# MIMXRT685S_cm33 register map
Vendor: nxp.com; File version: 1.0
CPU: CM33 r2p0, little endian, MPU, FPU, VTOR, 3 interrupt priority bits
Registers are 32-bit, read-write, reset 0x0 unless marked. A register's access mark holds for its fields unless they carry their own. Offsets are from the block's base; [hi:lo] are bit positions; {n}, {i} and the like mark numbered series; 'fields as' and 'values as' point back to an identical list.

## SYSCTL0 — system controller 0
Base 0x40002000
0x0C DSPSTALL reset 0x1
  [0] DSPSTALL — Run / Stall Register. . .
    0=RUN_MODE (Run (Normal) Mode.); 1=STALL_MODE
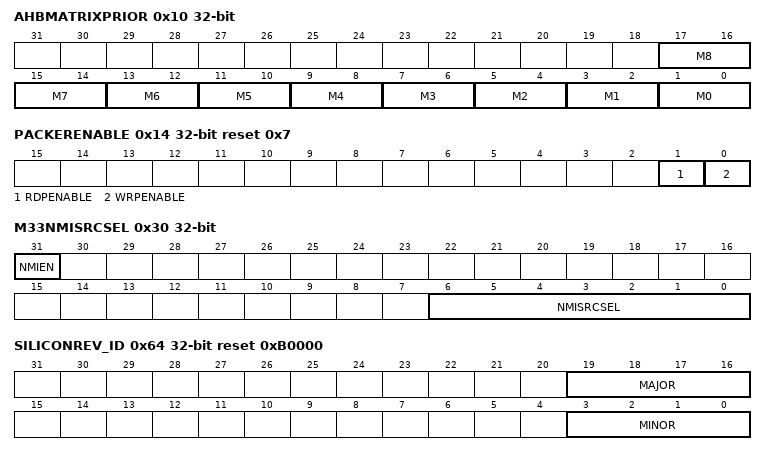
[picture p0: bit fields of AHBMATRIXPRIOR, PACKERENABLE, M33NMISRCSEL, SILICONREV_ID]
0x10 AHBMATRIXPRIOR — AHB matrix priority
  [2n+1:2n] M{n} (n=1..8) — Master {n} Priority. . . 0: 0, 1: 1, 2: 2, 3: 3.
  [1:0] M0 — Master 0 Priority. . . 0: 0, 1: 1, 2: 2, 3: 3. (0 High)
0x14 PACKERENABLE reset 0x7 — Packer enable for DSP RAM packer
  [1] RDPENABLE — Read Packer Enable
    0=DISABLED; 1=ENABLED
  [0] WRPENABLE — Write Packer Enable.
    0=DISABLED; 1=ENABLED
0x30 M33NMISRCSEL — M33 nmi source selection
  [31] NMIEN — NMI interrupt enable
    0=DISABLED (Disable NMI Interrupt); 1=ENABLED (Enable NMI Interrupt.)
  [6:0] NMISRCSEL — Selects one of the M33 interrupt sources as the NMI source. See M33 Interrupt Slot Table for Interrupt Slot Numers.
0x34 SYSTEM_STICK_CALIB — system stick calibration
  [25:0] SYSTEM_STICK_CALIB — Selects the system secure tick calibration value of the M33.
0x38 SYSTEM_NSTICK_CALIB — system nstick calibration
  [25:0] SYSTEM_NSTICK_CALIB — Selects the system non-secure tick calibration value of the M33.
0x60 PRODUCT_ID ro reset not defined
  [15:0] PRODUCT_ID — This register contains the product ID which is unique for each part number.
0x64 SILICONREV_ID ro reset 0xB0000
  [19:16] MAJOR — Silicon revision major tag. (IE, A, B, C, etc)
  [3:0] MINOR — Silicon revision minor tag. (IE, 0, 2, 3, etc)
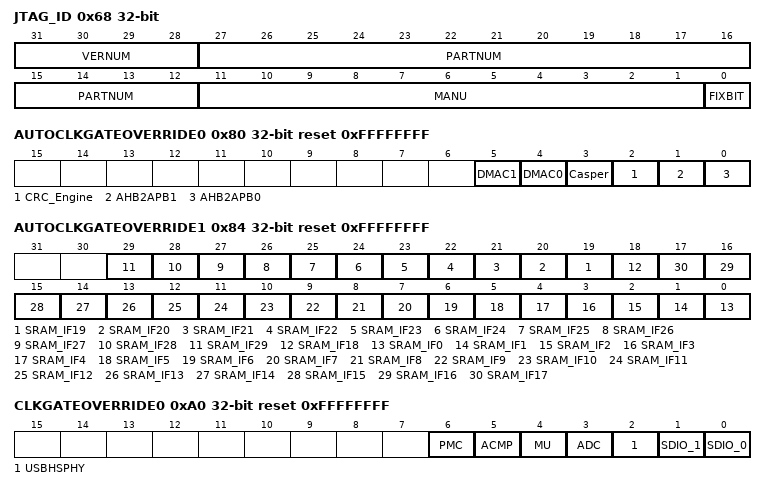
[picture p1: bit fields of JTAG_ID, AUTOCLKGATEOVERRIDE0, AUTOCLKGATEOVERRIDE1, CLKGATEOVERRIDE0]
0x68 JTAG_ID ro reset not defined
  [31:28] VERNUM — JTAG IDCODE version number
  [27:12] PARTNUM — JTAG IDCODE part number
  [11:1] MANU — JTAG IDCODE manufacturer identity
  [0] FIXBIT — JTAG IDCODE fix bit
0x80 AUTOCLKGATEOVERRIDE0 reset 0xFFFFFFFF — auto clock gating override 0
  [all] fields
    0=ENABLED (Enable Auto-Clk); 1=DISABLED (Disable Auto-Clk)
  [5] DMAC1 — auto clock gating enable
  [4] DMAC0 — auto clock gating enable
  [3] Casper — auto clock gating enable
  [2] CRC_Engine — auto clock gating enable
  [1] AHB2APB1 — auto clock gating enable
  [0] AHB2APB0 — auto clock gating enable
0x84 AUTOCLKGATEOVERRIDE1 reset 0xFFFFFFFF — auto clock gating override 1
  [n] SRAM_IF{n} (n=19..29) — auto clock gating enable
    0=ENABLED (Enable Auto-Clk); 1=DISABLED (Disable Auto-Clk)
  [18] SRAM_IF18 — auto clock gating enable
  [n] SRAM_IF{n} (n=0..17) — auto clock gating enable
    0=ENABLED (Enable Auto-Clk); 1=DISABLED (Disable Auto-Clk)
0xA0 CLKGATEOVERRIDE0 reset 0xFFFFFFFF — Clock gate override 0
  [all] fields
    0=NO_EFFECT; 1=OVERRIDE
  [6] PMC — pmc clock override
  [5] ACMP — acomparator clock override
  [4] MU — mu clock override
  [3] ADC — adc clock override
  [2] USBHSPHY — usbhsphy clock override
  [1] SDIO_1 — sdio 1 clock override
  [0] SDIO_0 — sdio 0 clock override
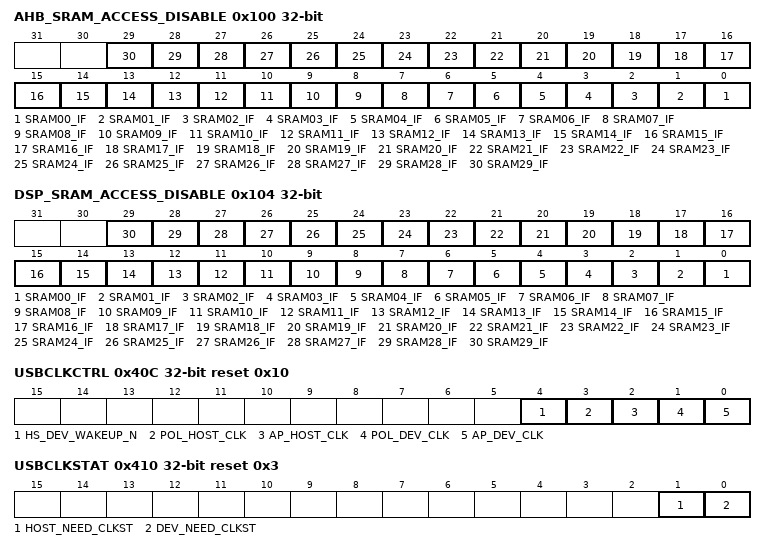
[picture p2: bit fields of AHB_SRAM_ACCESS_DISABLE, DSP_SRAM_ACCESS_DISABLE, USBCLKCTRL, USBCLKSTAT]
0x100 AHB_SRAM_ACCESS_DISABLE
  [all] fields
    0=ENABLED; 1=DISABLED
  [n] SRAM{n:02}_IF (n=0..29)
0x104 DSP_SRAM_ACCESS_DISABLE
  [all] fields
    0=ENABLED; 1=DISABLED
  [n] SRAM{n:02}_IF (n=0..29)
0x138 AHB_FLEXSPI_ACCESS_DISABLE — AHB Flexspi access control
  [0] AHB_FLEXSPI_ACCESS_DISABLE
    0=ENABLE (Enable AHB access to FLEXSPI); 1=DISABLE (Disable AHB access to FLEXSPI)
0x13C DSP_FLEXSPI_ACCESS_DISABLE — DSP Flexspi access control
  [0] DSP_FLEXSPI_ACCESS_DISABLE
    0=ENABLE (Enable DSP access to FLEXSPI); 1=DISABLE (Disable DSP access to FLEXSPI)
0x380 FLEXSPI_BOOTROM_SCRATCH0 — FLEXSPI NOR flash configure context register
  [31:0] scratch
0x40C USBCLKCTRL reset 0x10 — USB clock control
  [4] HS_DEV_WAKEUP_N — External user wake-up signal for device mode; asserting this signal (active low) will result in exiting the low power mode; input to asynchronous control logic
    0=FORCE_TO_WAKEUP (Forces USB0 PHY to wake-up.); 1=NORMAL (Normal USB0 PHY behavior.)
  [3] POL_HOST_CLK — USB0 HOST need clock polarity for triggering the USB1 wake-up interrupt
    0=FALLING_EDGE (Falling edge of host need_clock triggers wake-up.); 1=RISING_EDGE (Rising edge of host need_clock triggers wake-up.)
  [2] AP_HOST_CLK — USB0 Host need clock signal control
    0=UNDER_HW_CTRL (Under hardware control.); 1=FORCED_HIGH
  [1] POL_DEV_CLK — USB0 Device need clock polarity for triggering the USB1 wake-up interrupt
    0=FALLING_EDGE (Falling edge of device need_clock triggers wake-up.); 1=RISING_EDGE (Rising edge of device need_clock triggers wake-up.)
  [0] AP_DEV_CLK — USB0 Device need clock signal control
    0=UNDER_HW_CTRL (Under hardware control.); 1=FORCED_HIGH
0x410 USBCLKSTAT reset 0x3 — USB clock status
  [1] HOST_NEED_CLKST ro — USB Device Host USB_NEEDCLK signal status:
    0=LOW; 1=HIGH
  [0] DEV_NEED_CLKST ro — USB Device USB_NEEDCLK signal status:
    0=LOW; 1=HIGH
0x414 USBPHYPLL0LOCKTIMEDIV2 reset 0xCAFE — USB PHY PLL0 lock time division 2
  [15:0] LOCKTIMEDIV2 — USBPHYPLL0 Lock Time: Programmed lock time is in uS (micro-seconds) and is programmed as half the actual lock time value
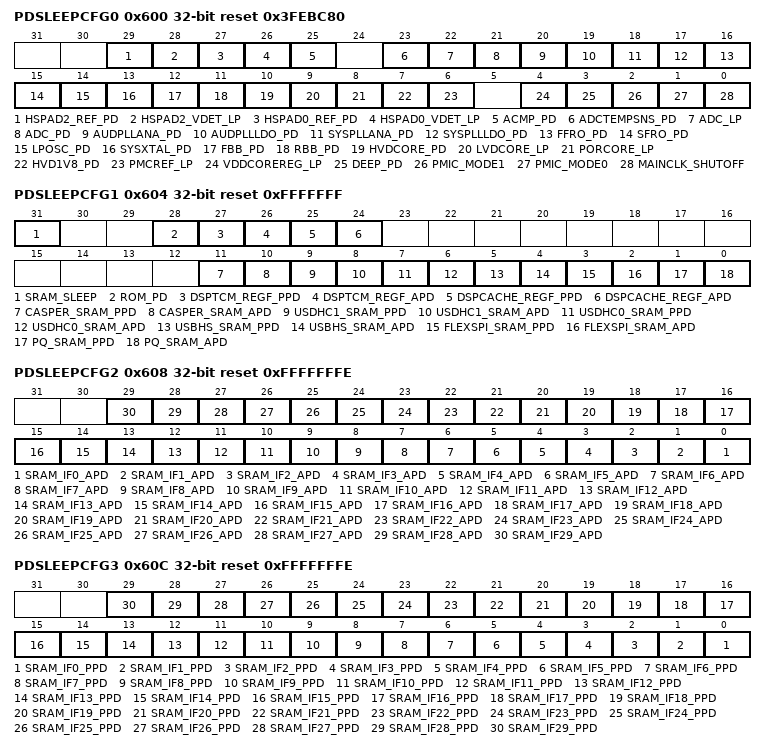
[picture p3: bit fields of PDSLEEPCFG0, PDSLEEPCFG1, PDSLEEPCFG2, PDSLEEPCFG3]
0x600 PDSLEEPCFG0 reset 0x3FEBC80 — Sleep configuration 0
  [29] HSPAD2_REF_PD
    0=ENABLED (High Speed Pad VREF Enabled); 1=POWER_DOWN (High Speed Pad VREF in Power Down)
  [28] HSPAD2_VDET_LP
    0=NORMAL_MODE (High Speed Pad VDET in Normal Mode); 1=SLEEP_MODE (High Speed Pad VDET in Sleep Mode)
  [27] HSPAD0_REF_PD
    values as HSPAD2_REF_PD
  [26] HSPAD0_VDET_LP
    values as HSPAD2_VDET_LP
  [25] ACMP_PD
    0=ENABLED; 1=POWER_DOWN
  [23] ADCTEMPSNS_PD
    0=ENABLED; 1=POWER_DOWN
  [22] ADC_LP
    0=ENABLED; 1=POWER_DOWN
  [21] ADC_PD
    0=ENABLED; 1=POWER_DOWN
  [20] AUDPLLANA_PD
    0=ENABLED; 1=POWER_DOWN
  [19] AUDPLLLDO_PD
    0=ENABLED; 1=POWER_DOWN
  [18] SYSPLLANA_PD
    0=ENABLED; 1=POWER_DOWN
  [17] SYSPLLLDO_PD
    0=ENABLED; 1=POWER_DOWN
  [16] FFRO_PD
    0=ENABLED; 1=POWER_DOWN
  [15] SFRO_PD
    0=ENABLED; 1=POWER_DOWN
  [14] LPOSC_PD
    0=ENABLED; 1=POWER_DOWN
  [13] SYSXTAL_PD
    0=ENABLED; 1=POWER_DOWN
  [12] FBB_PD — Writes to this bit in PDRUNCFG, but not PDSLEEPCFG, can be disabled by an OTP bit.
    0=ENABLED; 1=POWER_DOWN
  [11] RBB_PD — Writes to this bit in PDRUNCFG, but not PDSLEEPCFG, can be disabled by an OTP bit.
    0=ENABLED; 1=POWER_DOWN
  [10] HVDCORE_PD
    0=ENABLED; 1=POWER_DOWN
  [9] LVDCORE_LP
    0=HP_MODE (LVD0V85 HP Mode); 1=LP_MODE (LVD0V85 LP Mode.)
  [8] PORCORE_LP
    0=HP_MODE (LVD0V6 HP Mode); 1=LP_MODE (LVD0V6 LP Mode)
  [7] HVD1V8_PD
    0=ENABLED; 1=POWER_DOWN
  [6] PMCREF_LP
    0=HP_MODE (PMCREF HP Mode); 1=LP_MODE (PMCREF LP Mode)
  [4] VDDCOREREG_LP
    0=HP_MODE (VDDCOREREG HP Mode); 1=LP_MODE
  [3] DEEP_PD
    0=ENABLED; 1=POWER_DOWN
  [2] PMIC_MODE1
    0=SET_MODE1_0 (Set Mode1 to 0.); 1=SET_MODE1_1 (Set Mode1 to 1.)
  [1] PMIC_MODE0
    0=SET_MODE0_0 (Set Mode0 to '0'.); 1=SET_MODE0_1 (Set Mode0 to '1'.)
  [0] MAINCLK_SHUTOFF — main clock shut off
    0=CLOCK_ENABLED (Clocks enabled); 1=CLOCK_GATED (Clocks gated)
0x604 PDSLEEPCFG1 reset 0xFFFFFFF — Sleep configuration 1
  [31] SRAM_SLEEP — Needed when vddcore can be smaller than 0
    0=NORMAL_MODE (RAM Normal Mode); 1=SLEEP_MODE (RAM Sleep Mode.)
  [28] ROM_PD — array power and periph power
    0=ENABLED; 1=POWER_DOWN
  [27] DSPTCM_REGF_PPD — Peiph power
    0=ENABLED; 1=POWER_DOWN
  [26] DSPTCM_REGF_APD — Array power
    0=ENABLED; 1=POWER_DOWN
  [25] DSPCACHE_REGF_PPD — Peiph power
    0=ENABLED; 1=POWER_DOWN
  [24] DSPCACHE_REGF_APD — Array power
    0=ENABLED; 1=POWER_DOWN
  [11] CASPER_SRAM_PPD — Peiph power
    0=ENABLED; 1=POWER_DOWN
  [10] CASPER_SRAM_APD — Array power
    0=ENABLED; 1=POWER_DOWN
  [9] USDHC1_SRAM_PPD — Peiph power
    0=ENABLED; 1=POWER_DOWN
  [8] USDHC1_SRAM_APD — Array power
    0=ENABLED; 1=POWER_DOWN
  [7] USDHC0_SRAM_PPD — Peiph power
    0=ENABLED; 1=POWER_DOWN
  [6] USDHC0_SRAM_APD — Array power
    0=ENABLED; 1=POWER_DOWN
  [5] USBHS_SRAM_PPD — Peiph power
    0=ENABLED; 1=POWER_DOWN
  [4] USBHS_SRAM_APD — Array power
    0=ENABLED; 1=POWER_DOWN
  [3] FLEXSPI_SRAM_PPD — Peiph power
    0=ENABLED; 1=POWER_DOWN
  [2] FLEXSPI_SRAM_APD — Array power
    0=ENABLED; 1=POWER_DOWN
  [1] PQ_SRAM_PPD — Peiph power
    0=ENABLED; 1=POWER_DOWN
  [0] PQ_SRAM_APD — Array power
    0=ENABLED; 1=POWER_DOWN
0x608 PDSLEEPCFG2 reset 0xFFFFFFFE — Sleep configuration 2
  [all] fields
    0=ENABLED; 1=POWER_DOWN
  [n] SRAM_IF{n}_APD (n=0..29) — Array Power
0x60C PDSLEEPCFG3 reset 0xFFFFFFFE — Sleep configuration 3
  [all] fields
    0=ENABLED; 1=POWER_DOWN
  [n] SRAM_IF{n}_PPD (n=0..29) — Periph Power
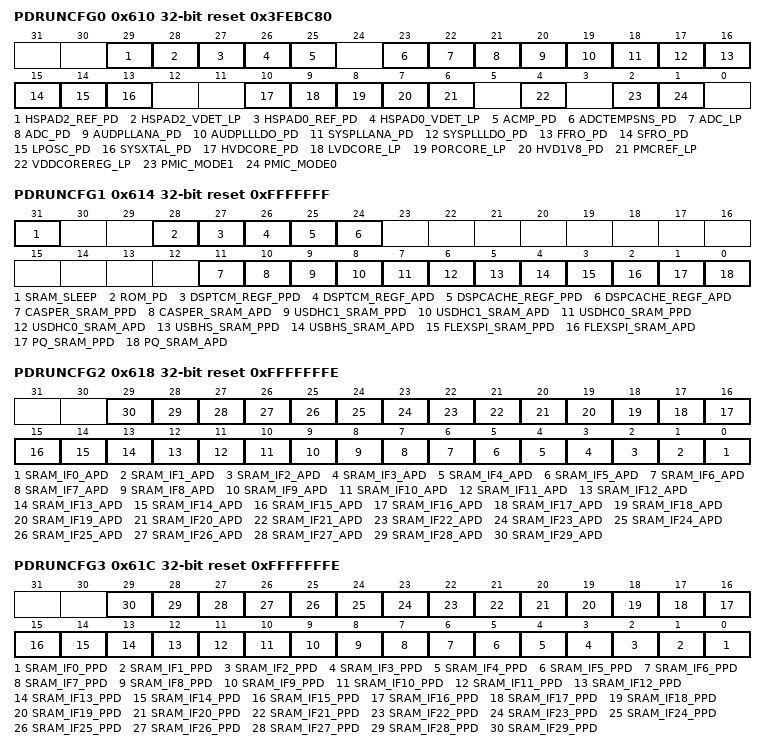
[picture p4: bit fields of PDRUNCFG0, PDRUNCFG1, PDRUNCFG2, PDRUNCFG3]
0x610 PDRUNCFG0 reset 0x3FEBC80 — Run configuration 0
  [29] HSPAD2_REF_PD — High speed Pad vdde2 reference blocks
    values as PDSLEEPCFG0.HSPAD2_REF_PD
  [28] HSPAD2_VDET_LP — High Speed Pad vdde2 voltage detect block
    values as PDSLEEPCFG0.HSPAD2_VDET_LP
  [27] HSPAD0_REF_PD — High speed Pad vdde0 reference blocks
    values as PDSLEEPCFG0.HSPAD2_REF_PD
  [26] HSPAD0_VDET_LP — High Speed Pad vdde0 voltage detect block
    values as PDSLEEPCFG0.HSPAD2_VDET_LP
  [25] ACMP_PD
    0=ENABLED; 1=POWER_DOWN
  [23] ADCTEMPSNS_PD
    0=ENABLED; 1=POWER_DOWN
  [22] ADC_LP
    0=ENABLED; 1=POWER_DOWN
  [21] ADC_PD
    0=ENABLED; 1=POWER_DOWN
  [20] AUDPLLANA_PD
    0=ENABLED; 1=POWER_DOWN
  [19] AUDPLLLDO_PD
    0=ENABLED; 1=POWER_DOWN
  [18] SYSPLLANA_PD
    0=ENABLED; 1=POWER_DOWN
  [17] SYSPLLLDO_PD
    0=ENABLED; 1=POWER_DOWN
  [16] FFRO_PD
    0=ENABLED; 1=POWER_DOWN
  [15] SFRO_PD
    0=ENABLED; 1=POWER_DOWN
  [14] LPOSC_PD
    0=ENABLED; 1=POWER_DOWN
  [13] SYSXTAL_PD
    0=ENABLED; 1=POWER_DOWN
  [10] HVDCORE_PD
    0=ENABLED; 1=POWER_DOWN
  [9] LVDCORE_LP
    0=HP_MODE (LVD0V85 HP Mode); 1=LP_MODE (LVD0V85 LP Mode.)
  [8] PORCORE_LP
    0=HP_MODE (LVD0V6 HP Mode); 1=LP_MODE (LVD0V6 LP Mode)
  [7] HVD1V8_PD
    0=ENABLED; 1=POWER_DOWN
  [6] PMCREF_LP
    0=HP_MODE (PMCREF HP Mode); 1=LP_MODE (PMCREF LP Mode)
  [4] VDDCOREREG_LP
    0=HP_MODE (VDDCOREREG HP Mode); 1=LP_MODE
  [2] PMIC_MODE1
    values as PDSLEEPCFG0.PMIC_MODE1
  [1] PMIC_MODE0
    0=SET_MODE0_0 (Set Mode0 to 0.); 1=SET_MODE0_1 (Set Mode0 to 1.)
0x614 PDRUNCFG1 reset 0xFFFFFFF — Run configuration 1
  fields as PDSLEEPCFG1
0x618 PDRUNCFG2 reset 0xFFFFFFFE — Run configuration 2
  fields as PDSLEEPCFG2
0x61C PDRUNCFG3 reset 0xFFFFFFFE — Run configuration 3
  fields as PDSLEEPCFG3
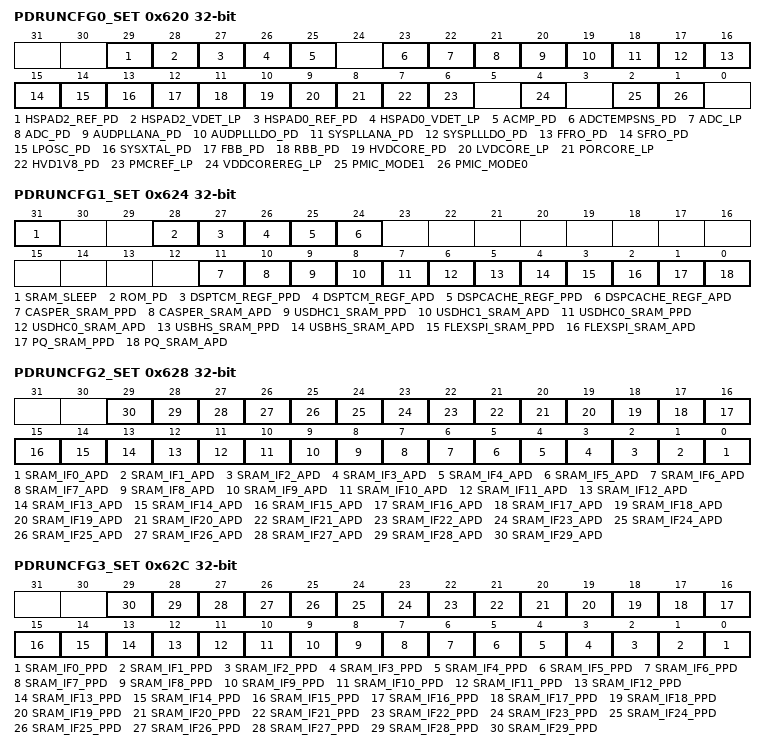
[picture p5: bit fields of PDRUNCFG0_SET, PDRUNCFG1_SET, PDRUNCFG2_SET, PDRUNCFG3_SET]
0x620 PDRUNCFG0_SET wo reset not defined — Run configuration 0 set
  [all] fields
    0=NO_EFFECT; 1=SET_PDRUNCFG0 (Sets the PDRUNCFG0 Bit)
  [29] HSPAD2_REF_PD
  [28] HSPAD2_VDET_LP
  [27] HSPAD0_REF_PD
  [26] HSPAD0_VDET_LP
  [25] ACMP_PD
  [23] ADCTEMPSNS_PD
  [22] ADC_LP
  [21] ADC_PD
  [20] AUDPLLANA_PD
  [19] AUDPLLLDO_PD
  [18] SYSPLLANA_PD
  [17] SYSPLLLDO_PD
  [16] FFRO_PD
  [15] SFRO_PD
  [14] LPOSC_PD
  [13] SYSXTAL_PD
  [12] FBB_PD
  [11] RBB_PD
  [10] HVDCORE_PD
  [9] LVDCORE_LP
  [8] PORCORE_LP
  [7] HVD1V8_PD
  [6] PMCREF_LP
  [4] VDDCOREREG_LP
  [2] PMIC_MODE1
  [1] PMIC_MODE0
0x624 PDRUNCFG1_SET wo reset not defined — Run configuration 1 set
  [all] fields
    0=NO_EFFECT; 1=SET_PDRUNCFG1 (Sets the PDRUNCFG1 Bit)
  [31] SRAM_SLEEP
  [28] ROM_PD — array power and periph power
  [27] DSPTCM_REGF_PPD — Peiph power
  [26] DSPTCM_REGF_APD — Array power
  [25] DSPCACHE_REGF_PPD — Peiph power
  [24] DSPCACHE_REGF_APD — Array power
  [11] CASPER_SRAM_PPD — Peiph power
  [10] CASPER_SRAM_APD — Array power
  [9] USDHC1_SRAM_PPD — Peiph power
  [8] USDHC1_SRAM_APD — Array power
  [7] USDHC0_SRAM_PPD — Peiph power
  [6] USDHC0_SRAM_APD — Array power
  [5] USBHS_SRAM_PPD — Peiph power
  [4] USBHS_SRAM_APD — Array power
  [3] FLEXSPI_SRAM_PPD — Peiph power
  [2] FLEXSPI_SRAM_APD — Array power
  [1] PQ_SRAM_PPD — Peiph power
  [0] PQ_SRAM_APD — Array power
0x628 PDRUNCFG2_SET wo reset not defined — Run configuration 2 set
  [all] fields
    0=NO_EFFECT; 1=SET_PDRUNCFG2 (Sets the PDRUNCFG2 Bit)
  [n] SRAM_IF{n}_APD (n=0..29) — Array Power
0x62C PDRUNCFG3_SET wo reset not defined — Run configuration 3 set
  [all] fields
    0=NO_EFFECT; 1=SET_PDRUNCFG3 (Sets the PDRUNCFG3 Bit)
  [n] SRAM_IF{n}_PPD (n=0..29) — Periph Power
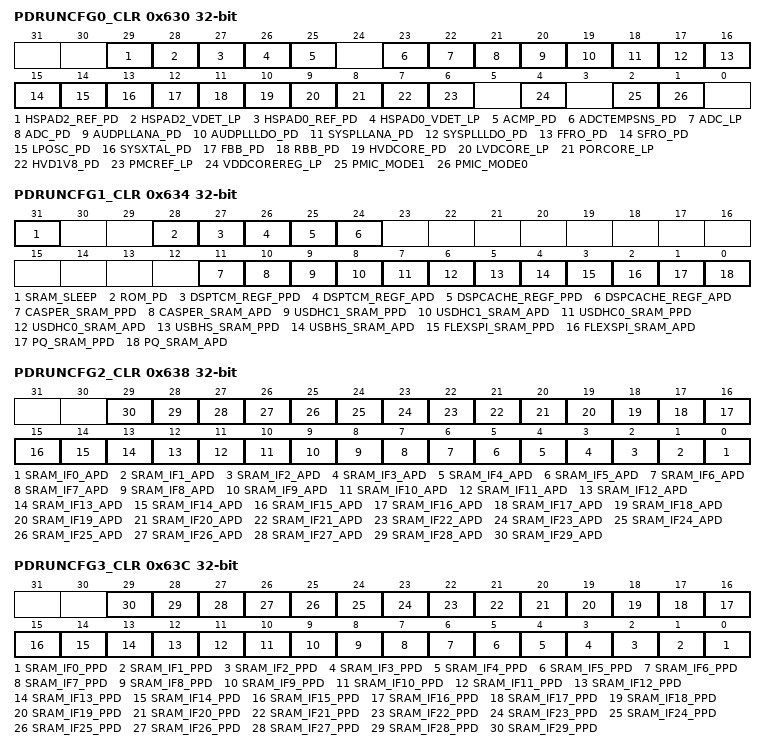
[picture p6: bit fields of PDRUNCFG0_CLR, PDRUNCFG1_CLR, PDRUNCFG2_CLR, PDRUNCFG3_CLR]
0x630 PDRUNCFG0_CLR wo reset not defined — Run configuration 0 clear
  [all] fields
    0=NO_EFFECT; 1=CLR_PDRUNCFG0 (Clears the PDRUNCFG0 Bit)
  [29] HSPAD2_REF_PD
  [28] HSPAD2_VDET_LP
  [27] HSPAD0_REF_PD
  [26] HSPAD0_VDET_LP
  [25] ACMP_PD
  [23] ADCTEMPSNS_PD
  [22] ADC_LP
  [21] ADC_PD
  [20] AUDPLLANA_PD
  [19] AUDPLLLDO_PD
  [18] SYSPLLANA_PD
  [17] SYSPLLLDO_PD
  [16] FFRO_PD
  [15] SFRO_PD
  [14] LPOSC_PD
  [13] SYSXTAL_PD
  [12] FBB_PD
  [11] RBB_PD
  [10] HVDCORE_PD
  [9] LVDCORE_LP
  [8] PORCORE_LP
  [7] HVD1V8_PD
  [6] PMCREF_LP
  [4] VDDCOREREG_LP
  [2] PMIC_MODE1
  [1] PMIC_MODE0
0x634 PDRUNCFG1_CLR wo reset not defined — Run configuration 1 clear
  [all] fields
    0=NO_EFFECT; 1=CLR_PDRUNCFG1 (Clears the PDRUNCFG1 Bit)
  [31] SRAM_SLEEP
  [28] ROM_PD — array power and periph power
  [27] DSPTCM_REGF_PPD — Peiph power
  [26] DSPTCM_REGF_APD — Array power
  [25] DSPCACHE_REGF_PPD — Peiph power
  [24] DSPCACHE_REGF_APD — Array power
  [11] CASPER_SRAM_PPD — Peiph power
  [10] CASPER_SRAM_APD — Array power
  [9] USDHC1_SRAM_PPD — Peiph power
  [8] USDHC1_SRAM_APD — Peiph power
  [7] USDHC0_SRAM_PPD — Array power
  [6] USDHC0_SRAM_APD — Array power
  [5] USBHS_SRAM_PPD — Peiph power
  [4] USBHS_SRAM_APD — Array power
  [3] FLEXSPI_SRAM_PPD — Peiph power
  [2] FLEXSPI_SRAM_APD — Array power
  [1] PQ_SRAM_PPD — Peiph power
  [0] PQ_SRAM_APD — Array power
0x638 PDRUNCFG2_CLR wo reset not defined — Run configuration 2 clear
  [all] fields
    0=NO_EFFECT; 1=CLR_PDRUNCFG2 (Clears the PDRUNCFG2 Bit)
  [n] SRAM_IF{n}_APD (n=0..29) — Array Power
0x63C PDRUNCFG3_CLR wo reset not defined — Run configuration 3 clear
  [all] fields
    0=NO_EFFECT; 1=CLR_PDRUNCFG3 (Clears the PDRUNCFG3 Bit)
  [n] SRAM_IF{n}_PPD (n=0..29) — Periph Power
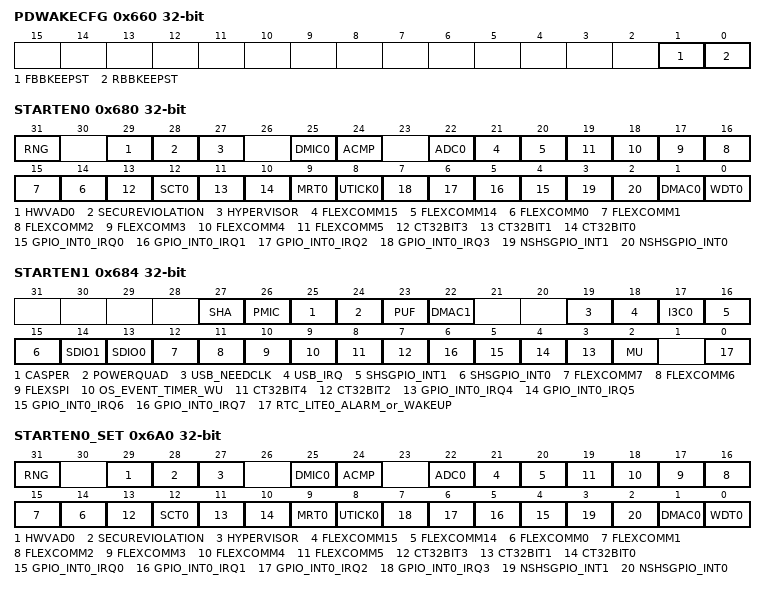
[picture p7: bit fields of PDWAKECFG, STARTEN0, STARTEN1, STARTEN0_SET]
0x660 PDWAKECFG — PD Wake Configuration
  [1] FBBKEEPST — FBB mode on wakeup
    0=Use value of FBB_PD in PDRUNCFG on wakeup; 1=Copy PDSLEEPCFG FBB_PD value to PDRUNCFG FBB_PD on wakeup to keep FBB state
  [0] RBBKEEPST — RBB mode on wakeup
    0=Use value of RBB_PD in PDRUNCFG on wakeup; 1=Copy PDSLEEPCFG RBB_PD value to PDRUNCFG RBB_PD on wakeup to keep RBB state
0x680 STARTEN0 — Start enable 0
  [all] fields
    0=DISABLED (disbale); 1=ENABLED
  [31] RNG
  [29] HWVAD0
  [28] SECUREVIOLATION
  [27] HYPERVISOR
  [25] DMIC0
  [24] ACMP
  [22] ADC0
  [21] FLEXCOMM15
  [20] FLEXCOMM14
  [n+14] FLEXCOMM{n} (n=0..5)
  [13] CT32BIT3
  [12] SCT0
  [11] CT32BIT1
  [10] CT32BIT0
  [9] MRT0
  [8] UTICK0
  [n+4] GPIO_INT0_IRQ{n} (n=0..3)
  [3] NSHSGPIO_INT1
  [2] NSHSGPIO_INT0
  [1] DMAC0
  [0] WDT0
0x684 STARTEN1 — Start enable 1
  [all] fields
    0=DISABLED (disbale); 1=ENABLED
  [27] SHA
  [26] PMIC
  [25] CASPER
  [24] POWERQUAD
  [23] PUF
  [22] DMAC1
  [19] USB_NEEDCLK
  [18] USB_IRQ
  [17] I3C0
  [16] SHSGPIO_INT1
  [15] SHSGPIO_INT0
  [14] SDIO1
  [13] SDIO0
  [12] FLEXCOMM7
  [11] FLEXCOMM6
  [10] FLEXSPI
  [9] OS_EVENT_TIMER_WU
  [8] CT32BIT4
  [7] CT32BIT2
  [n-1] GPIO_INT0_IRQ{n} (n=4..7)
  [2] MU
  [0] RTC_LITE0_ALARM_or_WAKEUP
0x6A0 STARTEN0_SET wo reset not defined — Start enable 0 set
  [all] fields
    0=NO_EFFECT; 1=SET_START_EN0 (Sets the START_EN0 Bit)
  [31] RNG
  [29] HWVAD0
  [28] SECUREVIOLATION
  [27] HYPERVISOR
  [25] DMIC0
  [24] ACMP
  [22] ADC0
  [21] FLEXCOMM15
  [20] FLEXCOMM14
  [n+14] FLEXCOMM{n} (n=0..5)
  [13] CT32BIT3
  [12] SCT0
  [11] CT32BIT1
  [10] CT32BIT0
  [9] MRT0
  [8] UTICK0
  [n+4] GPIO_INT0_IRQ{n} (n=0..3)
  [3] NSHSGPIO_INT1
  [2] NSHSGPIO_INT0
  [1] DMAC0
  [0] WDT0
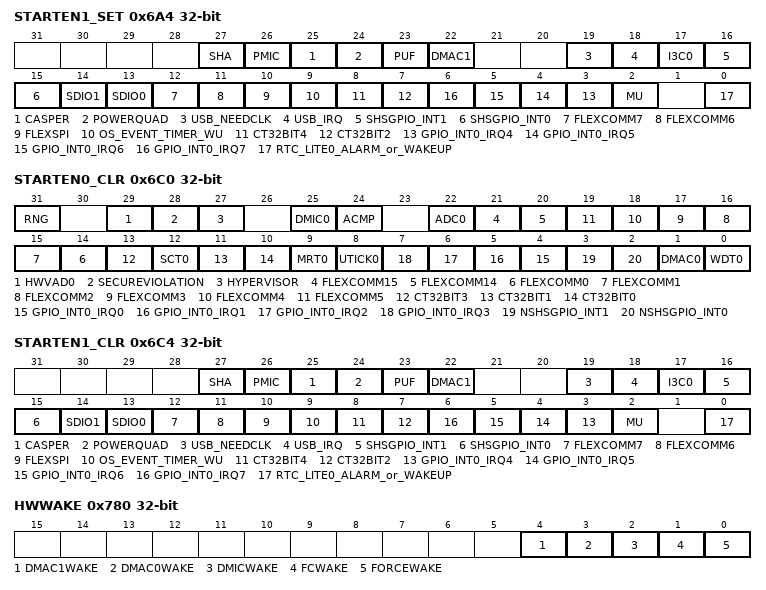
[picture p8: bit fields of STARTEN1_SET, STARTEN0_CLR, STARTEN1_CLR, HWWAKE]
0x6A4 STARTEN1_SET wo reset not defined — Start enable 1 set
  [all] fields
    0=NO_EFFECT; 1=SET_START_EN1 (Sets the START_EN1 Bit)
  [27] SHA
  [26] PMIC
  [25] CASPER
  [24] POWERQUAD
  [23] PUF
  [22] DMAC1
  [19] USB_NEEDCLK
  [18] USB_IRQ
  [17] I3C0
  [16] SHSGPIO_INT1
  [15] SHSGPIO_INT0
  [14] SDIO1
  [13] SDIO0
  [12] FLEXCOMM7
  [11] FLEXCOMM6
  [10] FLEXSPI
  [9] OS_EVENT_TIMER_WU
  [8] CT32BIT4
  [7] CT32BIT2
  [n-1] GPIO_INT0_IRQ{n} (n=4..7)
  [2] MU
  [0] RTC_LITE0_ALARM_or_WAKEUP
0x6C0 STARTEN0_CLR wo reset not defined — Start enable 0 clear
  [all] fields
    0=NO_EFFECT; 1=CLR_START_EN0 (Clears the START_EN0 Bit)
  [31] RNG
  [29] HWVAD0
  [28] SECUREVIOLATION
  [27] HYPERVISOR
  [25] DMIC0
  [24] ACMP
  [22] ADC0
  [21] FLEXCOMM15
  [20] FLEXCOMM14
  [n+14] FLEXCOMM{n} (n=0..5)
  [13] CT32BIT3
  [12] SCT0
  [11] CT32BIT1
  [10] CT32BIT0
  [9] MRT0
  [8] UTICK0
  [n+4] GPIO_INT0_IRQ{n} (n=0..3)
  [3] NSHSGPIO_INT1
  [2] NSHSGPIO_INT0
  [1] DMAC0
  [0] WDT0
0x6C4 STARTEN1_CLR wo reset not defined — Start enable 1 clear
  [all] fields
    0=NO_EFFECT; 1=CLR_START_EN1 (Clears the START_EN1 Bit)
  [27] SHA
  [26] PMIC
  [25] CASPER
  [24] POWERQUAD
  [23] PUF
  [22] DMAC1
  [19] USB_NEEDCLK
  [18] USB_IRQ
  [17] I3C0
  [16] SHSGPIO_INT1
  [15] SHSGPIO_INT0
  [14] SDIO1
  [13] SDIO0
  [12] FLEXCOMM7
  [11] FLEXCOMM6
  [10] FLEXSPI
  [9] OS_EVENT_TIMER_WU
  [8] CT32BIT4
  [7] CT32BIT2
  [n-1] GPIO_INT0_IRQ{n} (n=4..7)
  [2] MU
  [0] RTC_LITE0_ALARM_or_WAKEUP
0x710 MAINCLKSAFETY — Main Clock Safety
  [15:0] DELAY — Main Clock turn on delay for Deep Sleep wake up
0x780 HWWAKE — Hardware Wake-up control
  [4] DMAC1WAKE — Wake for DMAC1. When 1, DMAC1 being busy will cause peripheral clocking to remain running until DMAC1 completes. This is generally used in conjunction with bit 1 and/or 2 in order to prevent peripheral clocking from being shut down as soon as the cause of wake-up is cleared, but before DMAC1 has completed its related activity.
  [3] DMAC0WAKE — Wake for DMAC0. When 1, DMAC0 being busy will cause peripheral clocking to remain running until DMAC0 completes. This is generally used in conjunction with bit 1 and/or 2 in order to prevent peripheral clocking from being shut down as soon as the cause of wake-up is cleared, but before DMAC0 has completed its related activity.
  [2] DMICWAKE — Wake for Digital Microphone. When 1, the digital microphone input FIFO reaching the level specified by TRIGLVL of either channel will cause peripheral clocking to wake up temporarily while the related status is asserted.
  [1] FCWAKE — Wake for Flexcomm Interfaces. When 1, any Flexcomm Interface FIFO reaching the level specified by its own TXLVL will cause peripheral clocking to wake up temporarily while the related status is asserted.
  [0] FORCEWAKE — Force peripheral clocking to stay on during deep-sleep mode. When 1, clocking to peripherals is prevented from being shut down when the CPU enters deep-sleep mode. This is intended to allow a coprocessor to continue operating while the main CPU(s) are shut down.
0xE0C TEMPSENSORCTL — tempsensor ctrl
  [0] TSSRC — Temperature Sensor Source. . .
    0=ADC_TS (ADC Built-in Temperature Sensor.)
{0xE50+4i} BOOTSTATESEED{i} (i=0..7)
  [31:0] BOOTSTATESEED — A 256-bit random number set by boot ROM on each restart
{0xE70+4i} BOOTSTATEHMAC{i} (i=0..7)
  [31:0] BOOTSTATEHMAC — HMAC of boot state used for attestation
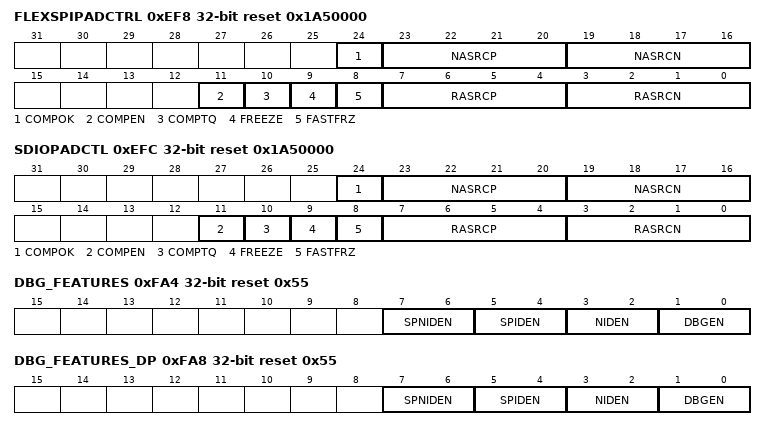
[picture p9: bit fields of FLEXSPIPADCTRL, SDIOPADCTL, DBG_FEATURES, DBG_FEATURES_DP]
0xEF8 FLEXSPIPADCTRL reset 0x1A50000 — FLEXSPI IO pads ctrl register
  [24] COMPOK ro — FLEXSPI pad compensation circuit status
  [23:20] NASRCP ro — FLEXSPI pad compensation circuit status
  [19:16] NASRCN ro — FLEXSPI pad compensation circuit status
  [11] COMPEN — Drive FLEXSPI pad compensation circuit
  [10] COMPTQ — Drive FLEXSPI pad compensation circuit
  [9] FREEZE — Drive FLEXSPI pad compensation circuit
  [8] FASTFRZ — Drive FLEXSPI pad compensation circuit
  [7:4] RASRCP — Drive FLEXSPI pad compensation circuit
  [3:0] RASRCN — Drive FLEXSPI pad compensation circuit
0xEFC SDIOPADCTL reset 0x1A50000 — sdio pad ctrl
  [24] COMPOK ro — SDIO Pad Compensation Circuit Status
  [23:20] NASRCP ro — SDIO Pad Compensation Circuit Status
  [19:16] NASRCN ro — SDIO Pad Compensation Circuit Status
  [11] COMPEN — Drives SDIO Pad Compensation Circuit
  [10] COMPTQ — Drives SDIO Pad Compensation Circuit
  [9] FREEZE — Drives SDIO Pad Compensation Circuit
  [8] FASTFRZ — Drives SDIO Pad Compensation Circuit
  [7:4] RASRCP — Drives SDIO Pad Compensation Circuit
  [3:0] RASRCN — Drives SDIO Pad Compensation Circuit
{0xF00+4i} DICEHWREG[{i}] (i=0..7) — DICE General Purpose 32-Bit Data Register
  [31:0] DICEHWREG
{0xF50+4i} UUID{i} (i=0..3) ro — UUIDn 32-Bit Data Register
  [31:0] uuid
0xF80 AESKEY_SRCSEL — AES key source selection
  [1:0] AESKEY_SRCSEL — AES Key Source Select:
0xF88 HASHHWKEYDISABLE — Hash hardware key disable
  [31:0] HASHHWKEYDISABLE — This register control the access to AES keys delivered through secret HW bus from PUF and OTP to AES engine
0xFA0 DBG_LOCKEN reset 0xA — Debug Write Lock registers
  [3:0] DBG_LOCKEN — Debug Write Lock the following registers: DBG_FEATURES DBG_FEATURES_DP CS_PROTTEST CS_PROTCPU0 CS_PROTCPU1 DBG_AUTH_SCRATCH 1010: Write Enabled (Unlocked) Any other value other than 1010, Write Disabled (Locked)
0xFA4 DBG_FEATURES reset 0x55 — Debug features control for the CM33
  [all] fields
    0=ENABLED; 1=DISBALED1 (disabled); 2=DISABLED2; 3=DISABLED3
  [7:6] SPNIDEN — CM33 SPNIDEN Enable Control
  [5:4] SPIDEN — CM33 SPID Enable Control
  [3:2] NIDEN — CM33 NID Enable Control
  [1:0] DBGEN — CM33 Debug Enable Control
0xFA8 DBG_FEATURES_DP reset 0x55 — Debug features duplicate
  fields as DBG_FEATURES
0xFAC HWUNLOCK_DISABLE reset not defined
  [3:0] HWUNLOCK_DISABLE — HW Unlock / Disable: Disable the OTP unlock for test, Teal and DSP debug Write any value to disable the allow testmode signal/allow CPU0 debug signal/allow CPU1 debug signal
0xFB4 CS_PROTCPU0 — Code Security for CPU0
  [31:0] CS_PROTCPU0 — Controls M33 AP Enable. Magic Value: 0x1234 5678
0xFB8 CS_PROTCPU1 — Code Security for CPU1
  [31:0] CS_PROTCPU1 — Controls HIFI4 AP Enable. Magic Value: 0x1234 5678
0xFC0 DBG_AUTH_SCRATCH — Debug authorization scratch
  [31:0] DBG_AUTH_SCRATCH — Debug authorization scratch register for S/W.
0xFD0 KEY_BLOCK reset 0x3CC35AA5
